# WS53 register map
File version: 0.1.0-experimental
Registers are 32-bit, read-write, no defined reset value unless marked. A register's access mark holds for its fields unless they carry their own. Offsets are from the block's base; [hi:lo] are bit positions; lines under a group give offsets from that group; {n}, {i} and the like mark numbered series.

## SPACC
Base 0x52010000
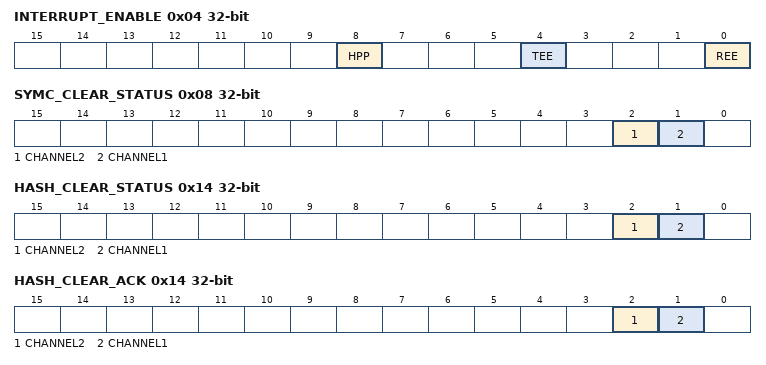
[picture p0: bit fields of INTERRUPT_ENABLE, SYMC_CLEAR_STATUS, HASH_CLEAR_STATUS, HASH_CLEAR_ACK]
0x04 INTERRUPT_ENABLE — Shared SPACC interrupt gates; SDK SYMC initialization selects REE or TEE. HPP is a header field, not an established WS53 IRQ route
  [8] HPP, [4] TEE, [0] REE
0x08 SYMC_CLEAR_STATUS ro — SYMC clear completion read view; SDK masks selected channel. Completion alone does not prove bus drain
  [2] CHANNEL2, [1] CHANNEL1
0x08 SYMC_CLEAR_ACK wo (alternate view of SYMC_CLEAR_STATUS) — Full-word clear acknowledgement command. SDK reuses the clear-request word including other bits; no W1C/reset semantics inferred and no implicit RMW interface
  [31:0] VALUE
0x14 HASH_CLEAR_STATUS ro — SDK polls the selected channel clear-finish bit; does not prove outstanding bus writes have drained
  [2] CHANNEL2, [1] CHANNEL1
0x14 HASH_CLEAR_ACK wo (alternate view of HASH_CLEAR_STATUS) — SDK writes the selected clear-finish bit to acknowledge; silicon W1C and reset semantics unknown
  [2] CHANNEL2, [1] CHANNEL1
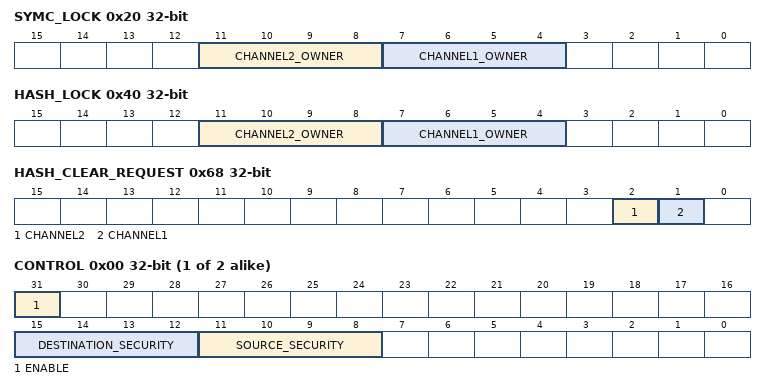
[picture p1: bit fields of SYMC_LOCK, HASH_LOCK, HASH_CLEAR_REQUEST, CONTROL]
0x20 SYMC_LOCK — SYMC owner nibbles: SDK requests REE1/TEE2 and checks readback. SDK unlock drops owner even on clear timeout; that is not a valid memory reclamation proof
  [11:8] CHANNEL2_OWNER, [7:4] CHANNEL1_OWNER
0x40 HASH_LOCK — Hardware channel owner nibbles: SDK requests 1 REE or 2 TEE and checks readback. Preserve other channels; not a software-only lock or a single-hart critical section
  [11:8] CHANNEL2_OWNER, [7:4] CHANNEL1_OWNER
0x60 SYMC_CLEAR_READ ro — SDK reads this full word before ORing the requested channel. Readback is not idle or completion
  [31:0] VALUE
0x60 SYMC_CLEAR_REQUEST wo (alternate view of SYMC_CLEAR_READ) — Full-word clear request command; no software-only clear/RMW/reset semantics
  [31:0] VALUE
0x68 HASH_CLEAR_REQUEST wo — Request channel clear. SDK lock incorrectly ignores timeout; no subsequent publication/reclamation is justified by a timed-out request
  [2] CHANNEL2, [1] CHANNEL1
{0x4100+0x100*i} SYMC_CHANNEL[{i}] (i=0..1) group — SYMC input configuration: index0 is SDK channel1, index1 channel2. Software contexts do not establish silicon availability or ownership
  0x00 CONTROL
    [31] ENABLE, [15:12] DESTINATION_SECURITY, [11:8] SOURCE_SECURITY
  0x04 OUTPUT_CONTROL — SDK writes 1 for DMA copy, 0 for cipher; other two-bit encodings unqualified
    [1:0] COPY_MODE
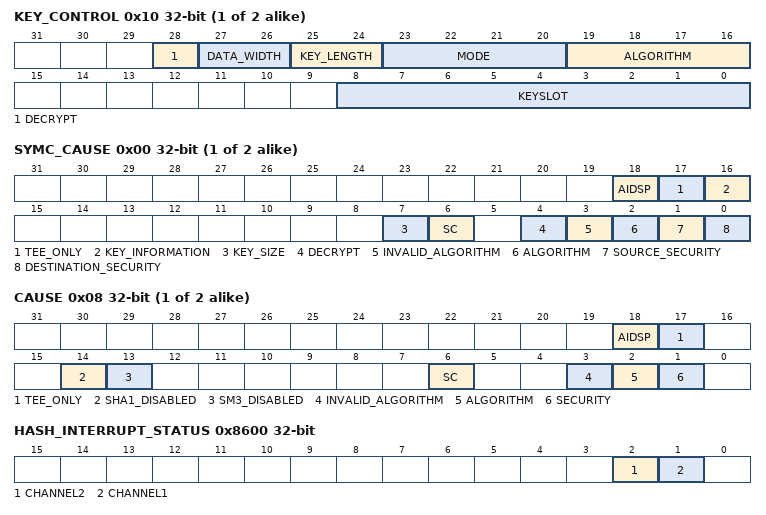
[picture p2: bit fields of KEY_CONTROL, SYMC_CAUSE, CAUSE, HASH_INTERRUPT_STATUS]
  0x10 KEY_CONTROL — Separate keyslot selector, not key bytes. Source table maps AES2/SM4=5, ECB1/CBC3/CTR6, width128=0 unlike unused BIT_WIDTH_128_REG macro. Valid encoding does not validate algorithm/key combinations
    [28] DECRYPT, [27:26] DATA_WIDTH, [25:24] KEY_LENGTH, [23:20] MODE, [19:16] ALGORITHM, [8:0] KEYSLOT
  0x20 NODE_BASE_HIGH — SDK writes zero high descriptor address. No nonzero high address support established
    [31:0] VALUE
  0x24 NODE_BASE_LOW
    [31:0] ADDRESS
  0x2C NODE_DEPTH — Source RMW low8 bits to two 32-byte input descriptors; silicon depth range unqualified
    [7:0] LENGTH
  0x30 WRITE_POINTER ro
    [7:0] POINTER
  0x30 SUBMIT wo (alternate view of WRITE_POINTER) — Input submission command; SDK publishes after output pointer, barriers and cache callbacks. Completion, timeout and pointer equality do not grant memory ownership
    [31:0] VALUE
  0x34 READ_POINTER ro
    [7:0] POINTER
{0x5100+0x100*i} HASH_CHANNEL[{i}] (i=0..1) group — HASH software profile: array index0 is SDK channel1, index1 is channel2. SDK counts do not establish silicon availability or exclusive ownership
  0x00 CONTROL — Channel control: SDK writes a full word with enable and security selector 0xa nonsecure or 0x5 secure; transitions and drain are unqualified
    [31] ENABLE, [11:8] SECURITY
  0x10 KEY_CONTROL — SDK state configuration: algorithm0xa SHA1,0xb SHA2,0xc SM3; mode0/1/2/3 for SHA2 224/256/384/512. Layout does not validate algorithms or grant a keyslot
    [23:20] MODE, [19:16] ALGORITHM, [9] HMAC, [3:0] KEYSLOT
  0x20 NODE_BASE_HIGH — Descriptor base high word; SDK writes zero. Implemented address width and nonzero high addresses are unknown
    [31:0] VALUE
  0x24 NODE_BASE_LOW
    [31:0] ADDRESS
  0x2C NODE_DEPTH — SDK programs two16-byte descriptors; this full-word source access is not a validated depth range
    [31:0] VALUE
  0x30 WRITE_POINTER ro — Submission pointer read view. SDK increments low8 bits modulo its configured depth; preserve unmodeled upper bits when constructing a submission
    [7:0] POINTER
  0x30 SUBMIT wo (alternate view of WRITE_POINTER) — DMA submission command, not ordinary mutable storage: SDK writes preserved readback with updated low8-bit pointer after barrier/cache-flush. No stop/drain/ownership guarantee
    [31:0] VALUE
  0x34 READ_POINTER ro
    [7:0] POINTER
  0xC0 DATA_LENGTH ro — SDK polls remaining data after pointers match and a delay; zero alone is not a bus-drain or safe-memory-reclamation proof
    [31:0] VALUE
{0x8060+0x10*i} HASH_ERROR[{i}] (i=0..1) group — Read-only interleaved security-domain diagnostics: legacy HASH_ERROR accessor name retained; index0 TEE,index1 REE. HASH CAUSE/STATUS addresses unchanged; SYMC views occupy preceding eight bytes. No error-clear commands
  0x00 SYMC_CAUSE ro
    [18] AIDSP, [17] TEE_ONLY, [16] KEY_INFORMATION, [7] KEY_SIZE, [6] SC, [4] DECRYPT, [3] INVALID_ALGORITHM, [2] ALGORITHM, [1] SOURCE_SECURITY, [0] DESTINATION_SECURITY
  0x04 SYMC_STATUS ro
    [19:16] CHANNEL
  0x08 CAUSE ro
    [18] AIDSP, [17] TEE_ONLY, [14] SHA1_DISABLED, [13] SM3_DISABLED, [6] SC, [3] INVALID_ALGORITHM, [2] ALGORITHM, [1] SECURITY
  0x0C STATUS ro — Error channel indication; header bit0 clear command intentionally withheld without an audited application write path
    [19:16] CHANNEL
0x8600 HASH_INTERRUPT_STATUS ro — Known application HASH completion bits. Raw read still returns the whole word; other channel availability unqualified
  [2] CHANNEL2, [1] CHANNEL1
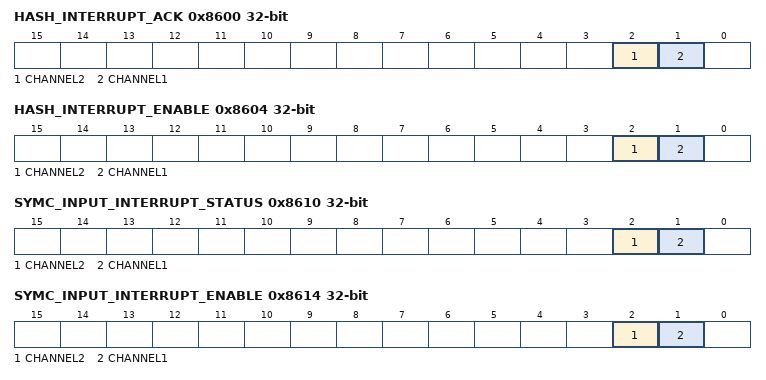
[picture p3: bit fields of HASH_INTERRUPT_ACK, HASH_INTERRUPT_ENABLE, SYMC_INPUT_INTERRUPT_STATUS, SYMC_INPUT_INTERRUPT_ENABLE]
0x8600 HASH_INTERRUPT_ACK wo (alternate view of HASH_INTERRUPT_STATUS) — SDK writes only the selected pending bit, including zero if absent; no inferred W1C, self-clear or reset value
  [2] CHANNEL2, [1] CHANNEL1
0x8604 HASH_INTERRUPT_ENABLE — Known application HASH completion gates; preserve every other bit on modification
  [2] CHANNEL2, [1] CHANNEL1
0x8610 SYMC_INPUT_INTERRUPT_STATUS ro — Source RAW input/no-output completion path; actual IRQ/ACK behavior not proved by header
  [2] CHANNEL2, [1] CHANNEL1
0x8610 SYMC_INPUT_INTERRUPT_ACK wo (alternate view of SYMC_INPUT_INTERRUPT_STATUS) — SDK masks low16 to selected channel but preserves upper16 read bits in full-word acknowledgement. No inferred W1C or read-modify-write API
  [31:0] VALUE
0x8614 SYMC_INPUT_INTERRUPT_ENABLE — Header field and optional CONFIG_SYMC_RAW_INT_SUPPORT path. Availability of optional IRQ route unqualified
  [2] CHANNEL2, [1] CHANNEL1
{0x9080+0x80*i} SYMC_IV[{i}] (i=0..1) group — CPU-read IV output state. SDK copies four little-endian words regardless of caller iv_len; this is not key storage
  {0x0+4j} WORD{j} ro (j=0..3)
    [31:0] VALUE
{0xA080+0x80*i} HASH_STATE[{i}] (i=0..1) group — HASH indexed state window: index0 is SDK channel1, index1 is channel2. State word count depends on algorithm; not key material ownership
  0x00 DATA
    [31:0] VALUE
  0x04 INDEX wo — SDK writes word index before each state read or write; not an auto-increment or ordinary RMW register
    [31:0] VALUE
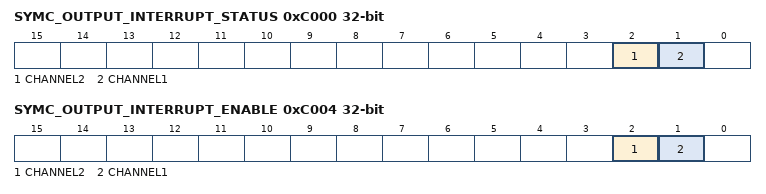
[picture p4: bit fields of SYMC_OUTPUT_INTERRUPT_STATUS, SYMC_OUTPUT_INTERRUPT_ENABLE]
0xC000 SYMC_OUTPUT_INTERRUPT_STATUS ro — Last output-node completion used by original polling and IRQ dispatch; no physical drain guarantee
  [2] CHANNEL2, [1] CHANNEL1
0xC000 SYMC_OUTPUT_INTERRUPT_ACK wo (alternate view of SYMC_OUTPUT_INTERRUPT_STATUS) — Full-word last-node acknowledgement; source retains reserved upper16 read bits, no W1C/reset inference
  [31:0] VALUE
0xC004 SYMC_OUTPUT_INTERRUPT_ENABLE
  [2] CHANNEL2, [1] CHANNEL1
{0xD000+0x100*i} SYMC_OUTPUT[{i}] (i=0..1) group — SYMC output descriptor ring: index0 SDK channel1,index1 channel2. Receives device writes into separately reserved DMA memory
  0x20 NODE_BASE_HIGH
    [31:0] VALUE
  0x24 NODE_BASE_LOW
    [31:0] ADDRESS
  0x28 NODE_DEPTH — Source programs two 16-byte output descriptors, not the 32-byte input format
    [7:0] LENGTH
  0x30 WRITE_POINTER ro
    [7:0] POINTER
  0x30 SUBMIT wo (alternate view of WRITE_POINTER) — Output descriptor publication command; must not expose read/modify as ordinary storage
    [31:0] VALUE
  0x34 READ_POINTER ro
    [7:0] POINTER
